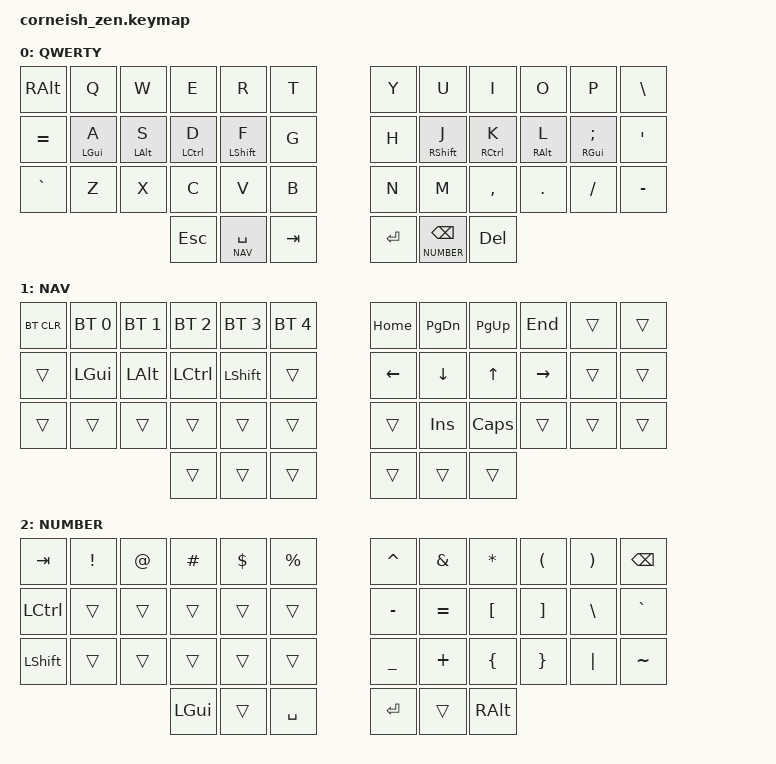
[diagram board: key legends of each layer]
#include <behaviors.dtsi>
#include <dt-bindings/zmk/keys.h>
#include <dt-bindings/zmk/bt.h>


#define QWERTY 0
#define NAV    1
#define NUMBER 2
#define SYMBOL 3
#define FNKEYS 4
#define MEDIA  4

#define NONE 0

/ {
  chosen {
    zmk,matrix_transform = &default_transform;
    //zmk,matrix_transform = &five_column_transform;
  };
};
/ {
        keymap {
                compatible = "zmk,keymap";

                default_layer {
                        label = "QWERTY";
// -----------------------------------------------------------------------------------------
// og - layout
// |  TAB |  Q  |  W  |  E  |  R  |  T  |   |  Y  |  U   |  I  |  O  |  P  | BKSP |
// | CTRL |  A  |  S  |  D  |  F  |  G  |   |  H  |  J   |  K  |  L  |  ;  |  '   |
// | SHFT |  Z  |  X  |  C  |  V  |  B  |   |  N  |  M   |  ,  |  .  |  /  | ESC  |
//                    | GUI | LWR | SPC |   | ENT | RSE  | ALT |
// -----------------------------------------------------------------------------------------
// | COMPOSE |  Q  |  W  |  E  |  R  |  T  |   |  Y  |  U   |  I  |  O  |  P  | \ |
// | = |  A  |  S  |  D  |  F  |  G  |   |  H  |  J   |  K  |  L  |  ;  |  '   |
// | ` |  Z  |  X  |  C  |  V  |  B  |   |  N  |  M   |  ,  |  .  |  /  | ESC  |
//                    | ESC | SPC | TAB |   | ENT | BKSP  | DEL  |
                        bindings = <
   &kp RALT  &kp Q &kp W &kp E &kp R &kp T   &kp Y &kp U  &kp I     &kp O   &kp P    &kp BSLH
   &kp EQUAL &mt LGUI A &mt LALT S &mt LCTRL D &mt LSHIFT F &kp G   &kp H &mt RSHIFT J &mt RCTRL K &mt RALT L &mt RGUI SEMI &kp SQT
   &kp GRAVE &kp Z &kp X &kp C &kp V &kp B   &kp N &kp M  &kp COMMA &kp DOT &kp FSLH &kp MINUS
                  &kp ESC &lt NAV SPC &kp TAB   &kp RET &lt NUMBER BKSP &kp DEL
                        >;
                };
                lower_layer {
                        label = " NAV ";
// -----------------------------------------------------------------------------------------
// | BTCLR| BT1 | BT2 | BT3 | BT4 | BT5 |       | HOME |  PgDn  |  PgUp  |  END  |    |    |
// |     | LGUI | LALT | LCTRL | LSHIFT |   |   | LFT | DWN |  UP | RGT |     |      |
// |     |     |     |     |     |     |   |     | INSERT | CAPSLOCK |     |     |      |
//                    |     |     |     |   |     |     |     |
                        bindings = <
   &bt BT_CLR &bt BT_SEL 0 &bt BT_SEL 1 &bt BT_SEL 2 &bt BT_SEL 3 &bt BT_SEL 4  &kp HOME &kp PAGE_DOWN &kp PAGE_UP    &kp END &trans &trans
   &trans     &kp LGUI     &kp LALT     &kp LCTRL    &kp LSHIFT 3 &trans        &kp LEFT &kp DOWN      &kp UP       &kp RIGHT &trans &trans
   &trans     &trans       &trans       &trans       &trans       &trans        &trans   &kp INSERT    &kp CAPSLOCK &trans &trans &trans
                          	        &trans &trans &trans &trans &trans &trans
                        >;
                };

                raise_layer {
                        label = "NUMBER";
// -----------------------------------------------------------------------------------------
// |  TAB |  !  |  @  |  #  |  $  |  %  |   |  ^  |  &  |  *  |  (  |  )  | BKSP |
// | CTRL |     |     |     |     |     |   |  -  |  =  |  [  |  ]  |  \  |  `   |
// | SHFT |     |     |     |     |     |   |  _  |  +  |  {  |  }  | "|" |  ~   |
//                    | GUI |     | SPC |   | ENT |     | ALT |
                        bindings = <
   &kp  TAB  &kp EXCL &kp AT &kp HASH &kp DLLR &kp PRCNT   &kp CARET &kp AMPS  &kp STAR &kp LPAR &kp RPAR &kp BSPC
   &kp LCTRL &trans   &trans &trans   &trans   &trans      &kp MINUS &kp EQUAL &kp LBKT &kp RBKT &kp BSLH &kp GRAVE
   &kp LSHFT &trans   &trans &trans   &trans   &trans      &kp UNDER &kp PLUS  &kp LBRC &kp RBRC &kp PIPE &kp TILDE
                    	     &kp LGUI &trans   &kp SPACE   &kp RET   &trans    &kp RALT
                        >;
                };
        };
};
